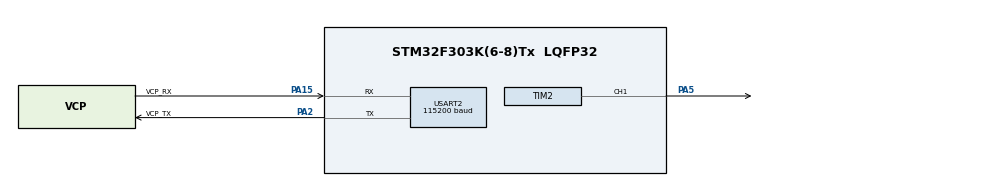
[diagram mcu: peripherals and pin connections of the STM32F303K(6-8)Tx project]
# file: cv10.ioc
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Dma.Request0=USART2_RX
Dma.Request1=USART2_TX
Dma.USART2_RX.0.Direction=DMA_PERIPH_TO_MEMORY
Dma.USART2_RX.0.Instance=DMA1_Channel6
Dma.USART2_RX.0.MemDataAlignment=DMA_MDATAALIGN_BYTE
Dma.USART2_RX.0.MemInc=DMA_MINC_ENABLE
Dma.USART2_RX.0.Mode=DMA_NORMAL
Dma.USART2_RX.0.PeriphDataAlignment=DMA_PDATAALIGN_BYTE
Dma.USART2_RX.0.PeriphInc=DMA_PINC_DISABLE
Dma.USART2_RX.0.Priority=DMA_PRIORITY_LOW
Dma.USART2_TX.1.Direction=DMA_MEMORY_TO_PERIPH
Dma.USART2_TX.1.Instance=DMA1_Channel7
Dma.USART2_TX.1.MemDataAlignment=DMA_MDATAALIGN_BYTE
Dma.USART2_TX.1.MemInc=DMA_MINC_ENABLE
Dma.USART2_TX.1.Mode=DMA_NORMAL
Dma.USART2_TX.1.PeriphDataAlignment=DMA_PDATAALIGN_BYTE
Dma.USART2_TX.1.PeriphInc=DMA_PINC_DISABLE
Dma.USART2_TX.1.Priority=DMA_PRIORITY_LOW
Mcu.Family=STM32F3
Mcu.Name=STM32F303K(6-8)Tx
Mcu.Package=LQFP32
NVIC.DMA1_Channel6_IRQn=true\:0\:0\:false\:false\:true\:false\:true
NVIC.DMA1_Channel7_IRQn=true\:0\:0\:false\:false\:true\:false\:true
NVIC.PriorityGroup=NVIC_PRIORITYGROUP_4
NVIC.TIM2_IRQn=true\:0\:0\:false\:false\:true\:true\:true
NVIC.USART2_IRQn=true\:0\:0\:false\:false\:true\:true\:true
PA13.GPIO_Label=SWDIO
PA13.Mode=Serial_Wire
PA13.Signal=SYS_JTMS-SWDIO
PA14.GPIO_Label=SWCLK
PA14.Mode=Serial_Wire
PA14.Signal=SYS_JTCK-SWCLK
PA15.GPIO_Label=VCP_RX
PA15.Mode=Asynchronous
PA15.Signal=USART2_RX
PA2.GPIO_Label=VCP_TX
PA2.Mode=Asynchronous
PA2.Signal=USART2_TX
PA5.Signal=S_TIM2_CH1_ETR
PF0\ /\ OSC_IN.GPIO_Label=MCO
PF0\ /\ OSC_IN.Mode=HSE-External-Clock-Source
PF0\ /\ OSC_IN.Signal=RCC_OSC_IN
ProjectManager.HeapSize=0x200
ProjectManager.StackSize=0x400
ProjectManager.TargetToolchain=STM32CubeIDE
RCC.AHBFreq_Value=8000000
RCC.APB1Freq_Value=8000000
RCC.APB2Freq_Value=8000000
RCC.CortexFreq_Value=8000000
RCC.HSE_VALUE=8000000
RCC.HSI_VALUE=8000000
RCC.SYSCLKFreq_VALUE=8000000
SH.S_TIM2_CH1_ETR.0=TIM2_CH1,PWM Generation1 CH1
TIM2.AutoReloadPreload=TIM_AUTORELOAD_PRELOAD_ENABLE
TIM2.Channel-PWM\ Generation1\ CH1=TIM_CHANNEL_1
TIM2.Period=99
TIM2.Prescaler=799
USART2.BaudRate=115200
USART2.VirtualMode-Asynchronous=VM_ASYNC
VP_TIM2_VS_ClockSourceINT.Mode=Internal
board=NUCLEO-F303K8

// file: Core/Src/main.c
/* USER CODE BEGIN Header */
/**
  ******************************************************************************
  * @file           : main.c
  * @brief          : Main program body
  ******************************************************************************
  * @attention
  *
  * <h2><center>&copy; Copyright (c) 2020 STMicroelectronics.
  * All rights reserved.</center></h2>
  *
  * This software component is licensed by ST under BSD 3-Clause license,
  * the "License"; You may not use this file except in compliance with the
  * License. You may obtain a copy of the License at:
  *                        opensource.org/licenses/BSD-3-Clause
  *
  ******************************************************************************
  */
/* USER CODE END Header */
#include "main.h"
#include "dma.h"
#include "tim.h"
#include "usart.h"
#include "gpio.h"

/* USER CODE BEGIN Includes */

#include "led_fade.h"
#include <string.h>
#include <stdio.h>
#include <stdlib.h>

/* USER CODE END Includes */

/* USER CODE BEGIN PD */
#define BUFF_SZ		40		// Size of command buffer
#define MSG_BUFF_SZ  150	// buffer to send from main
/* USER CODE END PD */

/* USER CODE BEGIN PV */

volatile uint16_t dma_occupied = 0;				// remaining space in DMA buffer

/* USER CODE END PV */

void SystemClock_Config(void);
/* USER CODE BEGIN PFP */

void proccesDmaData(uint8_t sign);		// callback to process one character of data

/* USER CODE END PFP */

int main(void)
{

  /* MCU Configuration--------------------------------------------------------*/

  /* Reset of all peripherals, Initializes the Flash interface and the Systick. */

  LL_APB2_GRP1_EnableClock(LL_APB2_GRP1_PERIPH_SYSCFG);
  LL_APB1_GRP1_EnableClock(LL_APB1_GRP1_PERIPH_PWR);

  NVIC_SetPriorityGrouping(NVIC_PRIORITYGROUP_4);

  /* System interrupt init*/

  /* Configure the system clock */
  SystemClock_Config();

  /* Initialize all configured peripherals */
  MX_GPIO_Init();
  MX_DMA_Init();
  MX_USART2_UART_Init();
  MX_TIM2_Init();
  /* USER CODE BEGIN 2 */

  // init USART
  USART2_RegisterCallback(proccesDmaData);
  DMA_init_for_USART2();

  // init global led fade state
  fade_init((LedFadeState*)&led_fade_state);

  //init timer
  LL_TIM_ClearFlag_UPDATE(TIM2);	//set by init function
  set_duty_cycle(0);				//initial PWM value
  LL_TIM_CC_EnableChannel(TIM2, LL_TIM_CHANNEL_CH1);	//enable PWM channels
  LL_TIM_EnableAllOutputs(TIM2);		//enable outputs
  LL_TIM_EnableIT_UPDATE(TIM2);			//enable update interrupt
  LL_TIM_EnableCounter(TIM2);			//enable timer
  /* USER CODE END 2 */

  /* Infinite loop */
  /* USER CODE BEGIN WHILE */
  uint8_t buff[MSG_BUFF_SZ];
  memset(buff, 0, MSG_BUFF_SZ);		// create buffer and set all to 0

  while (1)
  {

	LL_mDelay(200);

    /* USER CODE END WHILE */

  }
}

void SystemClock_Config(void)
{
  LL_FLASH_SetLatency(LL_FLASH_LATENCY_0);
  while(LL_FLASH_GetLatency()!= LL_FLASH_LATENCY_0)
  {
  }
  LL_RCC_HSI_Enable();

   /* Wait till HSI is ready */
  while(LL_RCC_HSI_IsReady() != 1)
  {

  }
  LL_RCC_HSI_SetCalibTrimming(16);
  LL_RCC_SetAHBPrescaler(LL_RCC_SYSCLK_DIV_1);
  LL_RCC_SetAPB1Prescaler(LL_RCC_APB1_DIV_1);
  LL_RCC_SetAPB2Prescaler(LL_RCC_APB1_DIV_1);
  LL_RCC_SetSysClkSource(LL_RCC_SYS_CLKSOURCE_HSI);

   /* Wait till System clock is ready */
  while(LL_RCC_GetSysClkSource() != LL_RCC_SYS_CLKSOURCE_STATUS_HSI)
  {

  }
  LL_Init1msTick(8000000);
  LL_SetSystemCoreClock(8000000);
}

/* USER CODE BEGIN 4 */

void processCmd(uint8_t *buff, uint16_t len) {
	if(strcmp(buff, "manual") == 0) {
		fade_manual((LedFadeState*)&led_fade_state);
	}
	else if(strncmp(buff, "PWM", 3) == 0) {	// compare only first 3 characters
		int t = atol(buff + 3);	// get number from command
		fade_set_target((LedFadeState*)&led_fade_state, (uint8_t)t);
	}
	else if(strcmp(buff, "auto") == 0) {
		fade_auto((LedFadeState*)&led_fade_state);
	}
}

// ignore or keep processing
typedef enum STATES_ {
	RECEIVING,
	IGNORING
}STATES;

void proccesDmaData(uint8_t sign)
{
	/* Process received data */
	static uint8_t buffer[BUFF_SZ];		//receive buffer
	static uint16_t ind = 0;			//current position
	static STATES state_machine = IGNORING;

	// check for overflow
	if(ind >= BUFF_SZ) {
		state_machine = IGNORING;
		ind = 0;
	}

	// start and ending '$' is not saved to buffer
	if(sign == '$' && state_machine != RECEIVING) {
		// upon receive of '$', start saving the characters
		state_machine = RECEIVING;
		memset(buffer, 0, BUFF_SZ);
		ind = 0;
	}
	else if((sign == '$' && state_machine == RECEIVING)) {
		// terminating '$', ignore rest of chars, process the commands
		state_machine = IGNORING;
		processCmd(buffer, ind);
	}
	else if(state_machine == RECEIVING) {
		// if in state RECEIVING, save to buffer, note: also saves begin/end characters
		buffer[ind++] = sign;
	}
}

/* USER CODE END 4 */

void Error_Handler(void)
{
}

/************************ (C) COPYRIGHT STMicroelectronics *****END OF FILE****/
